# Template register map
Vendor: VendorName Co.Ltd; Series: SeriesName; File version: 1.2
CPU: CM7 r0p1, little endian, MPU, FPU, 4 interrupt priority bits
Registers are 32-bit, read-write, no defined reset value unless marked. A register's access mark holds for its fields unless they carry their own. Offsets are from the block's base; [hi:lo] are bit positions; {n}, {i} and the like mark numbered series.

## SYSCON (part 2 of 2) — System Control
Base 0x40037000
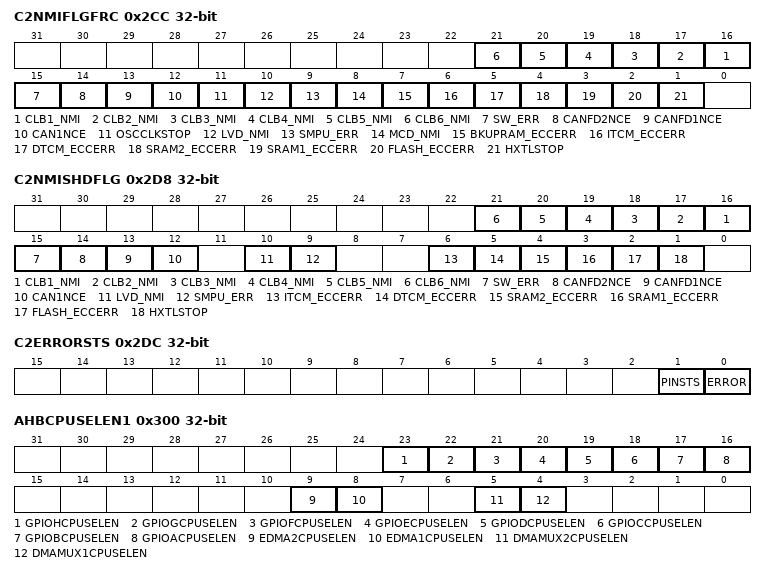
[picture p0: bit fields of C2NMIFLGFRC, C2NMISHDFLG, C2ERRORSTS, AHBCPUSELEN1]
0x2CC C2NMIFLGFRC ro — SYSCON CPU2 NMI flag force read only register
  [n+15] CLB{n}_NMI (n=1..6) — SYSCON CLB{n}_NMI bit: CLB{n} NMI flag force bit of CPU2
  [15] SW_ERR — SYSCON SW_ERR bit: SW ERR flag force bit of CPU2
  [14] CANFD2NCE — SYSCON CANFD2NCE bit: CANFD2 NCE flag force bit of CPU2
  [13] CANFD1NCE — SYSCON CANFD1NCE bit: CANFD1 NCE flag force bit of CPU2
  [12] CAN1NCE — SYSCON CAN1NCE bit: CAN1 NCE flag force bit of CPU2
  [11] OSCCLKSTOP — SYSCON OSCCLKSTOP bit: OSCCLK STOP flag force bit of CPU2
  [10] LVD_NMI — SYSCON LVD_NMI bit: LVD NMI flag force bit of CPU2
  [9] SMPU_ERR — SYSCON SMPU_ERR bit: SMPU ECCERR flag force bit of CPU2
  [8] MCD_NMI — SYSCON MCD_NMI bit: MCD NMI flag force bit of CPU2
  [7] BKUPRAM_ECCERR — SYSCON BKUPRAM_ECCERR bit: BKUPRAM ECCERR flag force bit of CPU2
  [6] ITCM_ECCERR — SYSCON ITCM_ECCERR bit: ITCM ECCERR flag force bit of CPU2
  [5] DTCM_ECCERR — SYSCON DTCM_ECCERR bit: DTCM ECCERR flag force bit of CPU2
  [4] SRAM2_ECCERR — SYSCON SRAM2_ECCERR bit: SRAM2 ECCERR flag force bit of CPU2
  [3] SRAM1_ECCERR — SYSCON SRAM1_ECCERR bit: SRAM1 ECCERR flag force bit of CPU2
  [2] FLASH_ECCERR — SYSCON FLASH_ECCERR bit: FLASH ECCERR flag force bit of CPU2
  [1] HXTLSTOP — SYSCON HXTLSTOP bit: HXTL STOP flag force bit of CPU2
0x2D0 C2NMIWDGCNT ro — SYSCON CPU2 NMIWDG read only register
  [15:0] NMIWDGCNT — SYSCON NMIWDGCNT[15:0] bit: NMIWDG counter of CPU2
0x2D4 C2NMIWDGPRD ro — SYSCON CPU2 NMIWDG period read only register
  [15:0] NMIWDGPRD — SYSCON NMIWDGPRD[15:0] bit: NMIWDG period of CPU2
0x2D8 C2NMISHDFLG ro — SYSCON CPU2 NMI flag shadow read only register
  [n+15] CLB{n}_NMI (n=1..6) — SYSCON CLB{n}_NMI bit: CLB{n} NMI shadow flag bit of CPU2
  [15] SW_ERR — SYSCON SW_ERR bit: SW ERR shadow flag bit of CPU2
  [14] CANFD2NCE — SYSCON CANFD2NCE bit: CANFD2 NCE shadow flag bit of CPU2
  [13] CANFD1NCE — SYSCON CANFD1NCE bit: CANFD1 NCE shadow flag bit of CPU2
  [12] CAN1NCE — SYSCON CAN1NCE bit: CAN1 NCE shadow flag bit of CPU2
  [10] LVD_NMI — SYSCON LVD_NMI bit: LVD NMI shadow flag bit of CPU2
  [9] SMPU_ERR — SYSCON SMPU_ERR bit: SMPU ECCERR shadow flag bit of CPU2
  [6] ITCM_ECCERR — SYSCON ITCM_ECCERR bit: ITCM ECCERR shadow flag bit of CPU2
  [5] DTCM_ECCERR — SYSCON DTCM_ECCERR bit: DTCM ECCERR shadow flag bit of CPU2
  [4] SRAM2_ECCERR — SYSCON SRAM2_ECCERR bit: SRAM2 ECCERR shadow flag bit of CPU2
  [3] SRAM1_ECCERR — SYSCON SRAM1_ECCERR bit: SRAM1 ECCERR shadow flag bit of CPU2
  [2] FLASH_ECCERR — SYSCON FLASH_ECCERR bit: FLASH ECCERR shadow flag bit of CPU2
  [1] HXTLSTOP — SYSCON HXTLSTOP bit: HXTL STOP shadow flag bit of CPU2
0x2DC C2ERRORSTS ro — SYSCON CPU2 error status read only register
  [1] PINSTS — SYSCON PINSTS bit: ERROR pin status bit of CPU2
  [0] ERROR — SYSCON ERROR bit: ERROR status bit of CPU2
0x2E8 C2ERRORCTL ro — SYSCON CPU2 error status control read only register
  [0] ERRORPOL — SYSCON ERRORPOL bit: ERROR polarity select bit of CPU2
0x300 AHBCPUSELEN1 — SYSCON AHB module CPU selection enable register 1
  [23] GPIOHCPUSELEN — SYSCON GPIOHCPUSELEN bit: GPIOH module CPU selection enable
  [22] GPIOGCPUSELEN — SYSCON GPIOGCPUSELEN bit: GPIOG module CPU selection enable
  [21] GPIOFCPUSELEN — SYSCON GPIOFCPUSELEN bit: GPIOF module CPU selection enable
  [20] GPIOECPUSELEN — SYSCON GPIOECPUSELEN bit: GPIOE module CPU selection enable
  [19] GPIODCPUSELEN — SYSCON GPIODCPUSELEN bit: GPIOD module CPU selection enable
  [18] GPIOCCPUSELEN — SYSCON GPIOCCPUSELEN bit: GPIOC module CPU selection enable
  [17] GPIOBCPUSELEN — SYSCON GPIOBCPUSELEN bit: GPIOB module CPU selection enable
  [16] GPIOACPUSELEN — SYSCON GPIOACPUSELEN bit: GPIOA module CPU selection enable
  [9] EDMA2CPUSELEN — SYSCON EDMA2CPUSELEN bit: EDMA2 module CPU selection enable
  [8] EDMA1CPUSELEN — SYSCON EDMA1CPUSELEN bit: EDMA1 module CPU selection enable
  [5] DMAMUX2CPUSELEN — SYSCON DMAMUX2CPUSELEN bit: DMAMUX2 module CPU selection enable
  [4] DMAMUX1CPUSELEN — SYSCON DMAMUX1CPUSELEN bit: DMAMUX1 module CPU selection enable
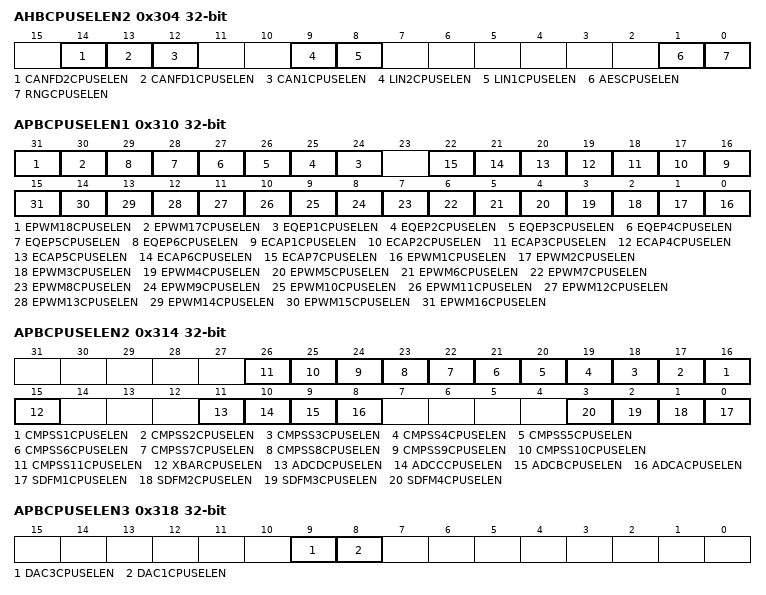
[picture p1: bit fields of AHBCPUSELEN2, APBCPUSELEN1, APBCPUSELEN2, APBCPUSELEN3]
0x304 AHBCPUSELEN2 — SYSCON AHB module CPU selection enable register 2
  [14] CANFD2CPUSELEN — SYSCON CANFD2CPUSELEN bit: CANFD2 module CPU selection enable
  [13] CANFD1CPUSELEN — SYSCON CANFD1CPUSELEN bit: CANFD1 module CPU selection enable
  [12] CAN1CPUSELEN — SYSCON CAN1CPUSELEN bit: CAN1 module CPU selection enable
  [9] LIN2CPUSELEN — SYSCON LIN2CPUSELEN bit: LIN2 module CPU selection enable
  [8] LIN1CPUSELEN — SYSCON LIN1CPUSELEN bit: LIN1 module CPU selection enable
  [1] AESCPUSELEN — SYSCON AESCPUSELEN bit: AES module CPU selection enable
  [0] RNGCPUSELEN — SYSCON RNGCPUSELEN bit: RNG module CPU selection enable
0x310 APBCPUSELEN1 — SYSCON APB module CPU selection enable register 1
  [31] EPWM18CPUSELEN — SYSCON EPWM18CPUSELEN bit: EPWM18 module CPU selection enable
  [30] EPWM17CPUSELEN — SYSCON EPWM17CPUSELEN bit: EPWM17 module CPU selection enable
  [n+23] EQEP{n}CPUSELEN (n=1..6) — SYSCON EQEP{n}CPUSELEN bit: EQEP{n} module CPU selection enable
  [n+15] ECAP{n}CPUSELEN (n=1..7) — SYSCON ECAP{n}CPUSELEN bit: ECAP{n} module CPU selection enable
  [n-1] EPWM{n}CPUSELEN (n=1..16) — SYSCON EPWM{n}CPUSELEN bit: EPWM{n} module CPU selection enable
0x314 APBCPUSELEN2 — SYSCON APB module CPU selection enable register 2
  [n+15] CMPSS{n}CPUSELEN (n=1..11) — SYSCON CMPSS{n}CPUSELEN bit: CMPSS{n} module CPU selection enable
  [15] XBARCPUSELEN — SYSCON XBARCPUSELEN bit: XBAR module CPU selection enable
  [11] ADCDCPUSELEN — SYSCON ADCDCPUSELEN bit: ADCD module CPU selection enable
  [10] ADCCCPUSELEN — SYSCON ADCCCPUSELEN bit: ADCC module CPU selection enable
  [9] ADCBCPUSELEN — SYSCON ADCBCPUSELEN bit: ADCB module CPU selection enable
  [8] ADCACPUSELEN — SYSCON ADCACPUSELEN bit: ADCA module CPU selection enable
  [n-1] SDFM{n}CPUSELEN (n=1..4) — SYSCON SDFM{n}CPUSELEN bit: SDFM{n} module CPU selection enable
0x318 APBCPUSELEN3 — SYSCON APB module CPU selection enable register 3
  [9] DAC3CPUSELEN — SYSCON DAC3CPUSELEN bit: DAC3 module CPU selection enable
  [8] DAC1CPUSELEN — SYSCON DAC1CPUSELEN bit: DAC1 module CPU selection enable
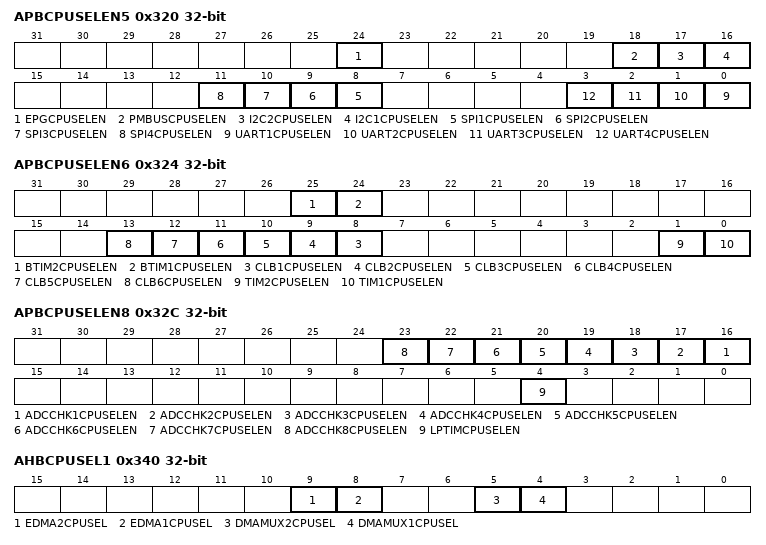
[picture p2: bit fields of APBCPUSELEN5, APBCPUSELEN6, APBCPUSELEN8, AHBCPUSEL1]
0x320 APBCPUSELEN5 — SYSCON APB module CPU selection enable register 5
  [24] EPGCPUSELEN — SYSCON EPGCPUSELEN bit: EPG module CPU selection enable
  [18] PMBUSCPUSELEN — SYSCON PMBUSCPUSELEN bit: PMBUS module CPU selection enable
  [17] I2C2CPUSELEN — SYSCON I2C2CPUSELEN bit: I2C2 module CPU selection enable
  [16] I2C1CPUSELEN — SYSCON I2C1CPUSELEN bit: I2C1 module CPU selection enable
  [n+7] SPI{n}CPUSELEN (n=1..4) — SYSCON SPI{n}CPUSELEN bit: SPI{n} module CPU selection enable
  [n-1] UART{n}CPUSELEN (n=1..4) — SYSCON UART{n}CPUSELEN bit: UART{n} module CPU selection enable
0x324 APBCPUSELEN6 — SYSCON APB module CPU selection enable register 6
  [25] BTIM2CPUSELEN — SYSCON BTIM2CPUSELEN bit: BTIM2 module CPU selection enable
  [24] BTIM1CPUSELEN — SYSCON BTIM1CPUSELEN bit: BTIM1 module CPU selection enable
  [n+7] CLB{n}CPUSELEN (n=1..6) — SYSCON CLB{n}CPUSELEN bit: CLB{n} module CPU selection enable
  [1] TIM2CPUSELEN — SYSCON TIM2CPUSELEN bit: TIM2 module CPU selection enable
  [0] TIM1CPUSELEN — SYSCON TIM1CPUSELEN bit: TIM1 module CPU selection enable
0x32C APBCPUSELEN8 — SYSCON APB module CPU selection enable register 8
  [n+15] ADCCHK{n}CPUSELEN (n=1..8) — SYSCON ADCCHK{n}CPUSELEN bit: ADC CHECKER{n} module CPU selection enable
  [4] LPTIMCPUSELEN — SYSCON LPTIMCPUSELEN bit: LPTIM module CPU selection enable
0x340 AHBCPUSEL1 — SYSCON AHB module CPU select register 1
  [9] EDMA2CPUSEL — SYSCON EDMA2CPUSEL bit: EDMA2 module CPU select
  [8] EDMA1CPUSEL — SYSCON EDMA1CPUSEL bit: EDMA1 module CPU select
  [5] DMAMUX2CPUSEL — SYSCON DMAMUX2CPUSEL bit: DMAMUX2 module CPU select
  [4] DMAMUX1CPUSEL — SYSCON DMAMUX1CPUSEL bit: DMAMUX1 module CPU select
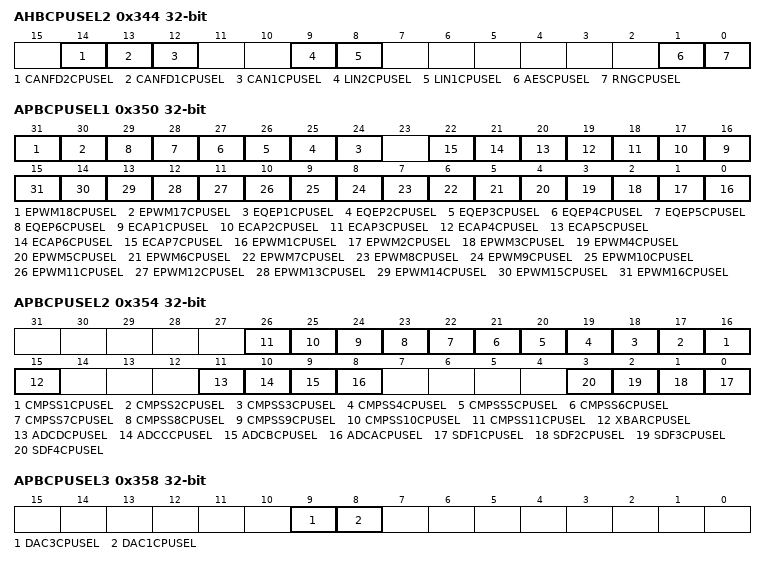
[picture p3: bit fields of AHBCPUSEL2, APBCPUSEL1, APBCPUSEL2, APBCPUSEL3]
0x344 AHBCPUSEL2 — SYSCON AHB module CPU select register 2
  [14] CANFD2CPUSEL — SYSCON CANFD2CPUSEL bit: CANFD2 module CPU select
  [13] CANFD1CPUSEL — SYSCON CANFD1CPUSEL bit: CANFD1 module CPU select
  [12] CAN1CPUSEL — SYSCON CAN1CPUSEL bit: CAN1 module CPU select
  [9] LIN2CPUSEL — SYSCON LIN2CPUSEL bit: LIN2 module CPU select
  [8] LIN1CPUSEL — SYSCON LIN1CPUSEL bit: LIN1 module CPU select
  [1] AESCPUSEL — SYSCON AESCPUSEL bit: AES module CPU select
  [0] RNGCPUSEL — SYSCON RNGCPUSEL bit: RNG module CPU select
0x350 APBCPUSEL1 — SYSCON APB module CPU select register 1
  [31] EPWM18CPUSEL — SYSCON EPWM18CPUSEL bit: EPWM18 module CPU select
  [30] EPWM17CPUSEL — SYSCON EPWM17CPUSEL bit: EPWM17 module CPU select
  [n+23] EQEP{n}CPUSEL (n=1..6) — SYSCON EQEP{n}CPUSEL bit: EQEP{n} module CPU select
  [n+15] ECAP{n}CPUSEL (n=1..7) — SYSCON ECAP{n}CPUSEL bit: ECAP{n} module CPU select
  [n-1] EPWM{n}CPUSEL (n=1..16) — SYSCON EPWM{n}CPUSEL bit: EPWM{n} module CPU select
0x354 APBCPUSEL2 — SYSCON APB module CPU select register 2
  [n+15] CMPSS{n}CPUSEL (n=1..11) — SYSCON CMPSS{n}CPUSEL bit: CMPSS{n} module CPU select
  [15] XBARCPUSEL — SYSCON XBARCPUSEL bit: XBAR module CPU select
  [11] ADCDCPUSEL — SYSCON ADCDCPUSEL bit: ADCD module CPU select
  [10] ADCCCPUSEL — SYSCON ADCCCPUSEL bit: ADCC module CPU select
  [9] ADCBCPUSEL — SYSCON ADCBCPUSEL bit: ADCB module CPU select
  [8] ADCACPUSEL — SYSCON ADCACPUSEL bit: ADCA module CPU select
  [n-1] SDF{n}CPUSEL (n=1..4) — SYSCON SDF{n}CPUSEL bit: SDF{n} module CPU select
0x358 APBCPUSEL3 — SYSCON APB module CPU select register 3
  [9] DAC3CPUSEL — SYSCON DAC3CPUSEL bit: DAC3 module CPU select
  [8] DAC1CPUSEL — SYSCON DAC1CPUSEL bit: DAC1 module CPU select
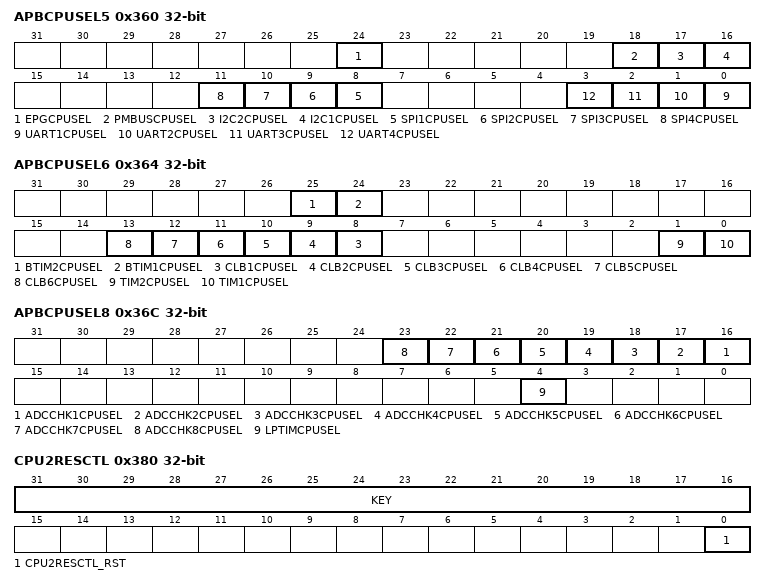
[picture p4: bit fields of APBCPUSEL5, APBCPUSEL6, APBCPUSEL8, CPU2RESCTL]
0x360 APBCPUSEL5 — SYSCON APB module CPU select register 5
  [24] EPGCPUSEL — SYSCON EPGCPUSEL bit: EPG module CPU select
  [18] PMBUSCPUSEL — SYSCON PMBUSCPUSEL bit: PMBUS module CPU select
  [17] I2C2CPUSEL — SYSCON I2C2CPUSEL bit: I2C2 module CPU select
  [16] I2C1CPUSEL — SYSCON I2C1CPUSEL bit: I2C1 module CPU select
  [n+7] SPI{n}CPUSEL (n=1..4) — SYSCON SPI{n}CPUSEL bit: SPI{n} module CPU select
  [n-1] UART{n}CPUSEL (n=1..4) — SYSCON UART{n}CPUSEL bit: UART{n} module CPU select
0x364 APBCPUSEL6 — SYSCON APB module CPU select register 6
  [25] BTIM2CPUSEL — SYSCON BTIM2CPUSEL bit: BTIM2 module CPU select
  [24] BTIM1CPUSEL — SYSCON BTIM1CPUSEL bit: BTIM1 module CPU select
  [n+7] CLB{n}CPUSEL (n=1..6) — SYSCON CLB{n}CPUSEL bit: CLB{n} module CPU select
  [1] TIM2CPUSEL — SYSCON TIM2CPUSEL bit: TIM2 module CPU select
  [0] TIM1CPUSEL — SYSCON TIM1CPUSEL bit: TIM1 module CPU select
0x36C APBCPUSEL8 — SYSCON APB module CPU select register 8
  [n+15] ADCCHK{n}CPUSEL (n=1..8) — SYSCON ADCCHK{n}CPUSEL bit: ADC CHECKER{n} module CPU select
  [4] LPTIMCPUSEL — SYSCON LPTIMCPUSEL bit: LPTIM module CPU select
0x380 CPU2RESCTL — SYSCON CPU2 reset control register
  [31:16] KEY wo — SYSCON KEY[15:0] bit: only when 0xA5A5 is written at high position can this register be written
  [0] CPU2RESCTL_RST — SYSCON CPU2RESCTL_RST bit: CPU2 reset control
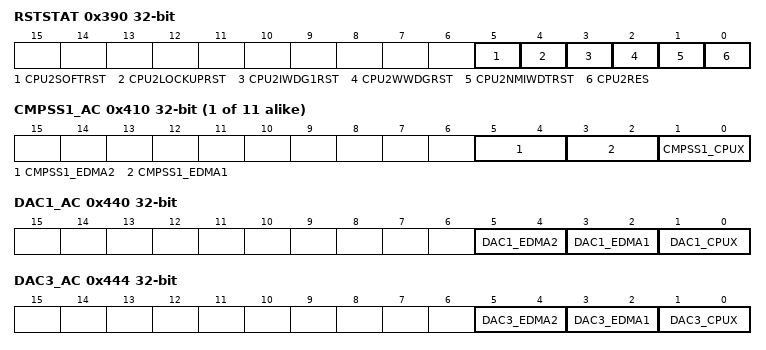
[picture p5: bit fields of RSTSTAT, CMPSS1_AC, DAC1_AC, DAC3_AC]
0x390 RSTSTAT — SYSCON CPU2 reset status register
  [5] CPU2SOFTRST — SYSCON CPU2SOFTRST bit: CPU2 was reseted by CPU2.SOFT
  [4] CPU2LOCKUPRST — SYSCON CPU2LOCKUPRST bit: CPU2 was reseted by CPU2.LOCKUP
  [3] CPU2IWDG1RST — SYSCON CPU2IWDG1RST bit: CPU2 was reseted by CPU2.IWDG1
  [2] CPU2WWDGRST — SYSCON CPU2WWDGRST bit: CPU2 was reseted by CPU2.WWDG
  [1] CPU2NMIWDTRST — SYSCON CPU2NMIWDTRST bit: CPU2 was reseted by CPU2.NMIWDT
  [0] CPU2RES ro — SYSCON CPU2RES bit: CPU2 reset status
0x400 ADCA_AC — SYSCON ADCA access control register
  [1:0] ADCA_CPUX — SYSCON ADCA_CPUX[1:0] bit: ADCA CPUx access privilege
0x404 ADCB_AC — SYSCON ADCB access control register
  [1:0] ADCB_CPUX — SYSCON ADCB_CPUX[1:0] bit: ADCB CPUx access privilege
0x408 ADCC_AC — SYSCON ADCC access control register
  [1:0] ADCC_CPUX — SYSCON ADCC_CPUX[1:0] bit: ADCC CPUx access privilege
0x40C ADCD_AC — SYSCON ADCD access control register
  [1:0] ADCD_CPUX — SYSCON ADCD_CPUX[1:0] bit: ADCD CPUx access privilege
{0x40C+4i} CMPSS{i}_AC (i=1..11) — SYSCON CMPSS{i} access control register
  [5:4] CMPSS{i}_EDMA2 — SYSCON CMPSS{i}_EDMA2[1:0] bit: CMPSS{i} EDMA2 access privilege
  [3:2] CMPSS{i}_EDMA1 — SYSCON CMPSS{i}_EDMA1[1:0] bit: CMPSS{i} EDMA1 access privilege
  [1:0] CMPSS{i}_CPUX — SYSCON CMPSS{i}_CPUX[1:0] bit: CMPSS{i} CPUx access privilege
0x440 DAC1_AC — SYSCON DAC1 access control register
  [5:4] DAC1_EDMA2 — SYSCON DAC1_EDMA2[1:0] bit: DAC1 EDMA2 access privilege
  [3:2] DAC1_EDMA1 — SYSCON DAC1_EDMA1[1:0] bit: DAC1 EDMA1 access privilege
  [1:0] DAC1_CPUX — SYSCON DAC1_CPUX[1:0] bit: DAC1 CPUx access privilege
0x444 DAC3_AC — SYSCON DAC3 access control register
  [5:4] DAC3_EDMA2 — SYSCON DAC3_EDMA2[1:0] bit: DAC3 EDMA2 access privilege
  [3:2] DAC3_EDMA1 — SYSCON DAC3_EDMA1[1:0] bit: DAC3 EDMA1 access privilege
  [1:0] DAC3_CPUX — SYSCON DAC3_CPUX[1:0] bit: DAC3 CPUx access privilege
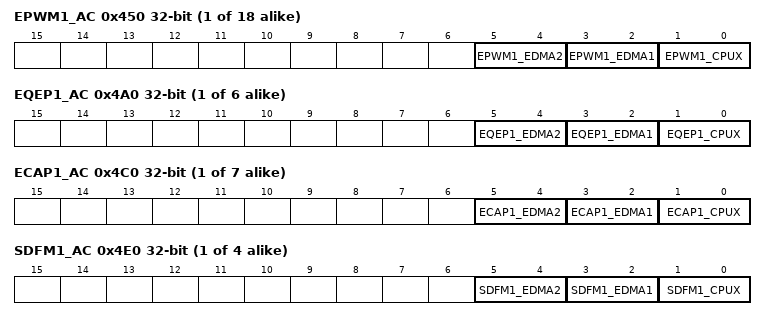
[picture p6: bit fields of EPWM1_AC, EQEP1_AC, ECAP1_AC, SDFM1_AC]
{0x44C+4i} EPWM{i}_AC (i=1..18) — SYSCON EPWM{i} access control register
  [5:4] EPWM{i}_EDMA2 — SYSCON EPWM{i}_EDMA2[1:0] bit: EPWM{i} EDMA2 access privilege
  [3:2] EPWM{i}_EDMA1 — SYSCON EPWM{i}_EDMA1[1:0] bit: EPWM{i} EDMA1 access privilege
  [1:0] EPWM{i}_CPUX — SYSCON EPWM{i}_CPUX[1:0] bit: EPWM{i} CPUx access privilege
{0x49C+4i} EQEP{i}_AC (i=1..6) — SYSCON EQEP{i} access control register
  [5:4] EQEP{i}_EDMA2 — SYSCON EQEP{i}_EDMA2[1:0] bit: EQEP{i} EDMA2 access privilege
  [3:2] EQEP{i}_EDMA1 — SYSCON EQEP{i}_EDMA1[1:0] bit: EQEP{i} EDMA1 access privilege
  [1:0] EQEP{i}_CPUX — SYSCON EQEP{i}_CPUX[1:0] bit: EQEP{i} CPUx access privilege
{0x4BC+4i} ECAP{i}_AC (i=1..7) — SYSCON ECAP{i} access control register
  [5:4] ECAP{i}_EDMA2 — SYSCON ECAP{i}_EDMA2[1:0] bit: ECAP{i} EDMA2 access privilege
  [3:2] ECAP{i}_EDMA1 — SYSCON ECAP{i}_EDMA1[1:0] bit: ECAP{i} EDMA1 access privilege
  [1:0] ECAP{i}_CPUX — SYSCON ECAP{i}_CPUX[1:0] bit: ECAP{i} CPUx access privilege
{0x4DC+4i} SDFM{i}_AC (i=1..4) — SYSCON SDFM{i} access control register
  [5:4] SDFM{i}_EDMA2 — SYSCON SDFM{i}_EDMA2[1:0] bit: SDFM{i} EDMA2 access privilege
  [3:2] SDFM{i}_EDMA1 — SYSCON SDFM{i}_EDMA1[1:0] bit: SDFM{i} EDMA1 access privilege
  [1:0] SDFM{i}_CPUX — SYSCON SDFM{i}_CPUX[1:0] bit: SDFM{i} CPUx access privilege
{0x4EC+4i} CLB{i}_AC (i=1..6) — SYSCON CLB{i} access control register
  [1:0] CLB{i}_CPUX — SYSCON CLB{i}_CPUX[1:0] bit: CLB{i} CPUx access privilege
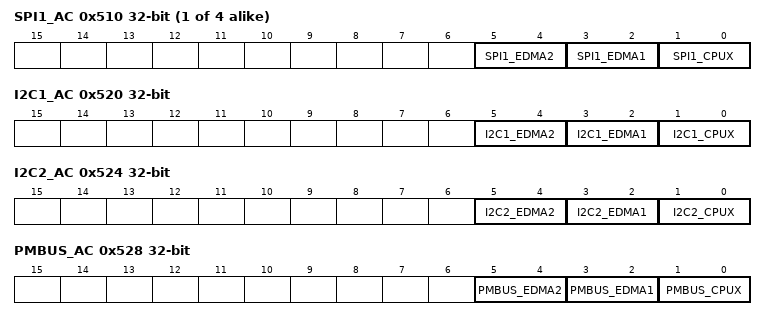
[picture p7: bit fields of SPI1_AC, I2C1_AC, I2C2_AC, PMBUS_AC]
{0x50C+4i} SPI{i}_AC (i=1..4) — SYSCON SPI{i} access control register
  [5:4] SPI{i}_EDMA2 — SYSCON SPI{i}_EDMA2[1:0] bit: SPI{i} EDMA2 access privilege
  [3:2] SPI{i}_EDMA1 — SYSCON SPI{i}_EDMA1[1:0] bit: SPI{i} EDMA1 access privilege
  [1:0] SPI{i}_CPUX — SYSCON SPI{i}_CPUX[1:0] bit: SPI{i} CPUx access privilege
0x520 I2C1_AC — SYSCON I2C1 access control register
  [5:4] I2C1_EDMA2 — SYSCON I2C1_EDMA2[1:0] bit: I2C1 EDMA2 access privilege
  [3:2] I2C1_EDMA1 — SYSCON I2C1_EDMA1[1:0] bit: I2C1 EDMA1 access privilege
  [1:0] I2C1_CPUX — SYSCON I2C1_CPUX[1:0] bit: I2C1 CPUx access privilege
0x524 I2C2_AC — SYSCON I2C2 access control register
  [5:4] I2C2_EDMA2 — SYSCON I2C2_EDMA2[1:0] bit: I2C2 EDMA2 access privilege
  [3:2] I2C2_EDMA1 — SYSCON I2C2_EDMA1[1:0] bit: I2C2 EDMA1 access privilege
  [1:0] I2C2_CPUX — SYSCON I2C2_CPUX[1:0] bit: I2C2 CPUx access privilege
0x528 PMBUS_AC — SYSCON PMBUS access control register
  [5:4] PMBUS_EDMA2 — SYSCON PMBUS_EDMA2[1:0] bit: PMBUS EDMA2 access privilege
  [3:2] PMBUS_EDMA1 — SYSCON PMBUS_EDMA1[1:0] bit: PMBUS EDMA1 access privilege
  [1:0] PMBUS_CPUX — SYSCON PMBUS_CPUX[1:0] bit: PMBUS CPUx access privilege
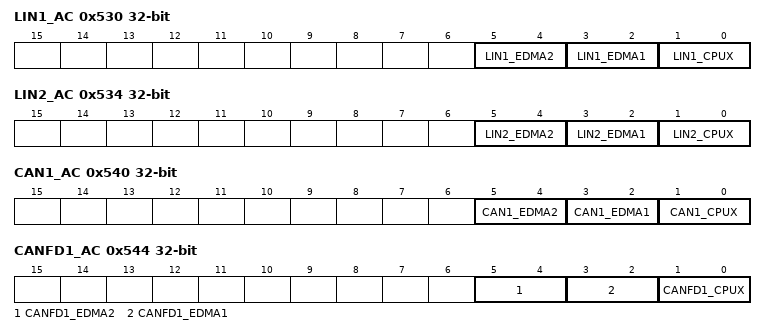
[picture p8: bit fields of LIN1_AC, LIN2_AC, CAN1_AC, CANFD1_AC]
0x530 LIN1_AC — SYSCON LIN1 access control register
  [5:4] LIN1_EDMA2 — SYSCON LIN1_EDMA2[1:0] bit: LIN1 EDMA2 access privilege
  [3:2] LIN1_EDMA1 — SYSCON LIN1_EDMA1[1:0] bit: LIN1 EDMA1 access privilege
  [1:0] LIN1_CPUX — SYSCON LIN1_CPUX[1:0] bit: LIN1 CPUx access privilege
0x534 LIN2_AC — SYSCON LIN2 access control register
  [5:4] LIN2_EDMA2 — SYSCON LIN2_EDMA2[1:0] bit: LIN2 EDMA2 access privilege
  [3:2] LIN2_EDMA1 — SYSCON LIN2_EDMA1[1:0] bit: LIN2 EDMA1 access privilege
  [1:0] LIN2_CPUX — SYSCON LIN2_CPUX[1:0] bit: LIN2 CPUx access privilege
0x540 CAN1_AC — SYSCON CAN1 access control register
  [5:4] CAN1_EDMA2 — SYSCON CAN1_EDMA2[1:0] bit: CAN1 EDMA2 access privilege
  [3:2] CAN1_EDMA1 — SYSCON CAN1_EDMA1[1:0] bit: CAN1 EDMA1 access privilege
  [1:0] CAN1_CPUX — SYSCON CAN1_CPUX[1:0] bit: CAN1 CPUx access privilege
0x544 CANFD1_AC — SYSCON CANFD1 access control register
  [5:4] CANFD1_EDMA2 — SYSCON CANFD1_EDMA2[1:0] bit: CANFD1 EDMA2 access privilege
  [3:2] CANFD1_EDMA1 — SYSCON CANFD1_EDMA1[1:0] bit: CANFD1 EDMA1 access privilege
  [1:0] CANFD1_CPUX — SYSCON CANFD1_CPUX[1:0] bit: CANFD1 CPUx access privilege
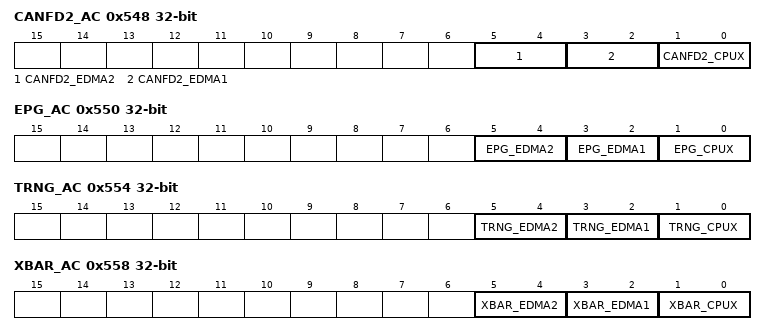
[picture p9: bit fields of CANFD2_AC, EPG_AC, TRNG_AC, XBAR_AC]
0x548 CANFD2_AC — SYSCON CANFD2 access control register
  [5:4] CANFD2_EDMA2 — SYSCON CANFD2_EDMA2[1:0] bit: CANFD2 EDMA2 access privilege
  [3:2] CANFD2_EDMA1 — SYSCON CANFD2_EDMA1[1:0] bit: CANFD2 EDMA1 access privilege
  [1:0] CANFD2_CPUX — SYSCON CANFD2_CPUX[1:0] bit: CANFD2 CPUx access privilege
0x550 EPG_AC — SYSCON EPG access control register
  [5:4] EPG_EDMA2 — SYSCON EPG_EDMA2[1:0] bit: EPG EDMA2 access privilege
  [3:2] EPG_EDMA1 — SYSCON EPG_EDMA1[1:0] bit: EPG EDMA1 access privilege
  [1:0] EPG_CPUX — SYSCON EPG_CPUX[1:0] bit: EPG CPUx access privilege
0x554 TRNG_AC — SYSCON TRNG access control register
  [5:4] TRNG_EDMA2 — SYSCON TRNG_EDMA2[1:0] bit: TRNG EDMA2 access privilege
  [3:2] TRNG_EDMA1 — SYSCON TRNG_EDMA1[1:0] bit: TRNG EDMA1 access privilege
  [1:0] TRNG_CPUX — SYSCON TRNG_CPUX[1:0] bit: TRNG CPUx access privilege
0x558 XBAR_AC — SYSCON XBAR access control register
  [5:4] XBAR_EDMA2 — SYSCON XBAR_EDMA2[1:0] bit: XBAR EDMA2 access privilege
  [3:2] XBAR_EDMA1 — SYSCON XBAR_EDMA1[1:0] bit: XBAR EDMA1 access privilege
  [1:0] XBAR_CPUX — SYSCON XBAR_CPUX[1:0] bit: XBAR CPUx access privilege
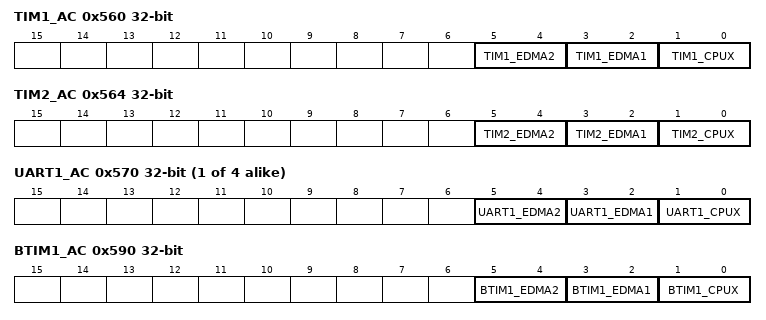
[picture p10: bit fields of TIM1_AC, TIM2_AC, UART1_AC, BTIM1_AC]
0x560 TIM1_AC — SYSCON TIM1 access control register
  [5:4] TIM1_EDMA2 — SYSCON TIM1_EDMA2[1:0] bit: TIM1 EDMA2 access privilege
  [3:2] TIM1_EDMA1 — SYSCON TIM1_EDMA1[1:0] bit: TIM1 EDMA1 access privilege
  [1:0] TIM1_CPUX — SYSCON TIM1_CPUX[1:0] bit: TIM1 CPUx access privilege
0x564 TIM2_AC — SYSCON TIM2 access control register
  [5:4] TIM2_EDMA2 — SYSCON TIM2_EDMA2[1:0] bit: TIM2 EDMA2 access privilege
  [3:2] TIM2_EDMA1 — SYSCON TIM2_EDMA1[1:0] bit: TIM2 EDMA1 access privilege
  [1:0] TIM2_CPUX — SYSCON TIM2_CPUX[1:0] bit: TIM2 CPUx access privilege
0x56C LPTIM_AC — SYSCON LPTIM access control register
  [1:0] LPTIM_CPUX — SYSCON LPTIM_CPUX[1:0] bit: LPTIM CPUx access privilege
{0x56C+4i} UART{i}_AC (i=1..4) — SYSCON UART{i} access control register
  [5:4] UART{i}_EDMA2 — SYSCON UART{i}_EDMA2[1:0] bit: UART{i} EDMA2 access privilege
  [3:2] UART{i}_EDMA1 — SYSCON UART{i}_EDMA1[1:0] bit: UART{i} EDMA1 access privilege
  [1:0] UART{i}_CPUX — SYSCON UART{i}_CPUX[1:0] bit: UART{i} CPUx access privilege
0x580 EDMA1_AC — SYSCON EDMA1 access control register
  [1:0] EDMA1_CPUX — SYSCON EDMA1_CPUX[1:0] bit: EDMA1 CPUx access privilege
0x584 EDMA2_AC — SYSCON EDMA2 access control register
  [1:0] EDMA2_CPUX — SYSCON EDMA2_CPUX[1:0] bit: EDMA2 CPUx access privilege
0x588 DMAMUX1_AC — SYSCON DMAMUX1 access control register
  [1:0] DMAMUX1_CPUX — SYSCON DMAMUX1_CPUX[1:0] bit: DMAMUX1 CPUx access privilege
0x58C DMAMUX2_AC — SYSCON DMAMUX2 access control register
  [1:0] DMAMUX2_CPUX — SYSCON DMAMUX2_CPUX[1:0] bit: DMAMUX2 CPUx access privilege
0x590 BTIM1_AC — SYSCON BTIM1 access control register
  [5:4] BTIM1_EDMA2 — SYSCON BTIM1_EDMA2[1:0] bit: BTIM1 EDMA2 access privilege
  [3:2] BTIM1_EDMA1 — SYSCON BTIM1_EDMA1[1:0] bit: BTIM1 EDMA1 access privilege
  [1:0] BTIM1_CPUX — SYSCON BTIM1_CPUX[1:0] bit: BTIM1 CPUx access privilege
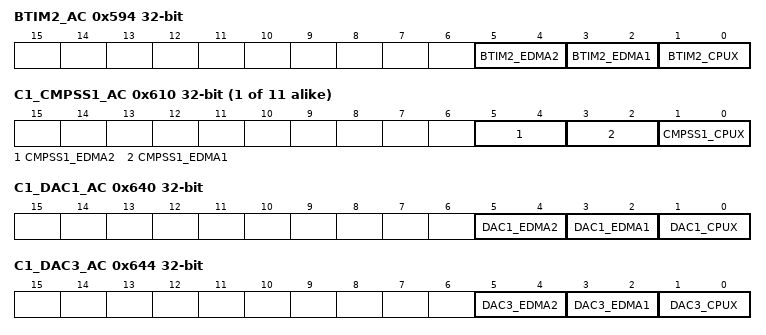
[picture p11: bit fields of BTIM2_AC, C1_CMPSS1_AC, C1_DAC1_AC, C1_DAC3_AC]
0x594 BTIM2_AC — SYSCON BTIM2 access control register
  [5:4] BTIM2_EDMA2 — SYSCON BTIM2_EDMA2[1:0] bit: BTIM2 EDMA2 access privilege
  [3:2] BTIM2_EDMA1 — SYSCON BTIM2_EDMA1[1:0] bit: BTIM2 EDMA1 access privilege
  [1:0] BTIM2_CPUX — SYSCON BTIM2_CPUX[1:0] bit: BTIM2 CPUx access privilege
0x5FC PERIPH_AC_LOCK — SYSCON access control lock register
  [0] LOCK_AC_WR — SYSCON LOCK_AC_WR bit: CPUx peripheral access control register access privilege
0x600 C1_ADCA_AC ro — SYSCON CPU1 ADCA access control read only register
  [1:0] ADCA_CPUX — SYSCON ADCA_CPUX[1:0] bit: ADCA CPUx access privilege of CPU1
0x604 C1_ADCB_AC ro — SYSCON CPU1 ADCB access control read only register
  [1:0] ADCB_CPUX — SYSCON ADCB_CPUX[1:0] bit: ADCB CPUx access privilege of CPU1
0x608 C1_ADCC_AC ro — SYSCON CPU1 ADCC access control read only register
  [1:0] ADCC_CPUX — SYSCON ADCC_CPUX[1:0] bit: ADCC CPUx access privilege of CPU1
0x60C C1_ADCD_AC ro — SYSCON CPU1 ADCD access control read only register
  [1:0] ADCD_CPUX — SYSCON ADCD_CPUX[1:0] bit: ADCD CPUx access privilege of CPU1
{0x60C+4i} C1_CMPSS{i}_AC ro (i=1..11) — SYSCON CPU1 CMPSS{i} access control read only register
  [5:4] CMPSS{i}_EDMA2 — SYSCON CMPSS{i}_EDMA2[1:0] bit: CMPSS{i} EDMA2 access privilege of CPU1
  [3:2] CMPSS{i}_EDMA1 — SYSCON CMPSS{i}_EDMA1[1:0] bit: CMPSS{i} EDMA1 access privilege of CPU1
  [1:0] CMPSS{i}_CPUX — SYSCON CMPSS{i}_CPUX[1:0] bit: CMPSS{i} CPUx access privilege of CPU1
0x640 C1_DAC1_AC ro — SYSCON CPU1 DAC1 access control read only register
  [5:4] DAC1_EDMA2 — SYSCON DAC1_EDMA2[1:0] bit: DAC1 EDMA2 access privilege of CPU1
  [3:2] DAC1_EDMA1 — SYSCON DAC1_EDMA1[1:0] bit: DAC1 EDMA1 access privilege of CPU1
  [1:0] DAC1_CPUX — SYSCON DAC1_CPUX[1:0] bit: DAC1 CPUx access privilege of CPU1
0x644 C1_DAC3_AC ro — SYSCON CPU1 DAC3 access control read only register
  [5:4] DAC3_EDMA2 — SYSCON DAC3_EDMA2[1:0] bit: DAC3 EDMA2 access privilege of CPU1
  [3:2] DAC3_EDMA1 — SYSCON DAC3_EDMA1[1:0] bit: DAC3 EDMA1 access privilege of CPU1
  [1:0] DAC3_CPUX — SYSCON DAC3_CPUX[1:0] bit: DAC3 CPUx access privilege of CPU1
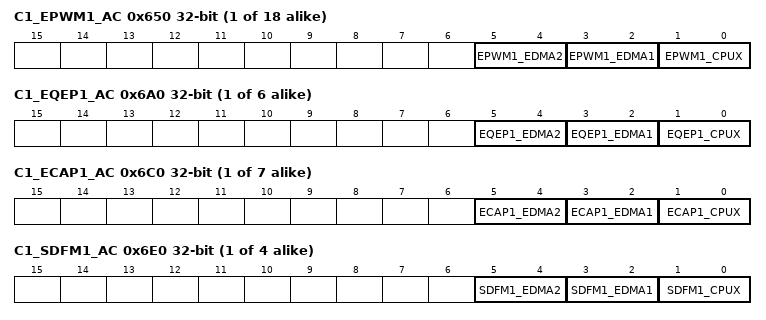
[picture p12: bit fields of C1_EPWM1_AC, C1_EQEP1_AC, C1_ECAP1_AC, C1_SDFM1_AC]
{0x64C+4i} C1_EPWM{i}_AC ro (i=1..18) — SYSCON CPU1 EPWM{i} access control read only register
  [5:4] EPWM{i}_EDMA2 — SYSCON EPWM{i}_EDMA2[1:0] bit: EPWM{i} EDMA2 access privilege of CPU1
  [3:2] EPWM{i}_EDMA1 — SYSCON EPWM{i}_EDMA1[1:0] bit: EPWM{i} EDMA1 access privilege of CPU1
  [1:0] EPWM{i}_CPUX — SYSCON EPWM{i}_CPUX[1:0] bit: EPWM{i} CPUx access privilege of CPU1
{0x69C+4i} C1_EQEP{i}_AC ro (i=1..6) — SYSCON CPU1 EQEP{i} access control read only register
  [5:4] EQEP{i}_EDMA2 — SYSCON EQEP{i}_EDMA2[1:0] bit: EQEP{i} EDMA2 access privilege of CPU1
  [3:2] EQEP{i}_EDMA1 — SYSCON EQEP{i}_EDMA1[1:0] bit: EQEP{i} EDMA1 access privilege of CPU1
  [1:0] EQEP{i}_CPUX — SYSCON EQEP{i}_CPUX[1:0] bit: EQEP{i} CPUx access privilege of CPU1
{0x6BC+4i} C1_ECAP{i}_AC ro (i=1..7) — SYSCON CPU1 ECAP{i} access control read only register
  [5:4] ECAP{i}_EDMA2 — SYSCON ECAP{i}_EDMA2[1:0] bit: ECAP{i} EDMA2 access privilege of CPU1
  [3:2] ECAP{i}_EDMA1 — SYSCON ECAP{i}_EDMA1[1:0] bit: ECAP{i} EDMA1 access privilege of CPU1
  [1:0] ECAP{i}_CPUX — SYSCON ECAP{i}_CPUX[1:0] bit: ECAP{i} CPUx access privilege of CPU1
{0x6DC+4i} C1_SDFM{i}_AC ro (i=1..4) — SYSCON CPU1 SDFM{i} access control read only register
  [5:4] SDFM{i}_EDMA2 — SYSCON SDFM{i}_EDMA2[1:0] bit: SDFM{i} EDMA2 access privilege of CPU1
  [3:2] SDFM{i}_EDMA1 — SYSCON SDFM{i}_EDMA1[1:0] bit: SDFM{i} EDMA1 access privilege of CPU1
  [1:0] SDFM{i}_CPUX — SYSCON SDFM{i}_CPUX[1:0] bit: SDFM{i} CPUx access privilege of CPU1
{0x6EC+4i} C1_CLB{i}_AC ro (i=1..6) — SYSCON CPU1 CLB{i} access control read only register
  [1:0] CLB{i}_CPUX — SYSCON CLB{i}_CPUX[1:0] bit: CLB{i} CPUx access privilege of CPU1
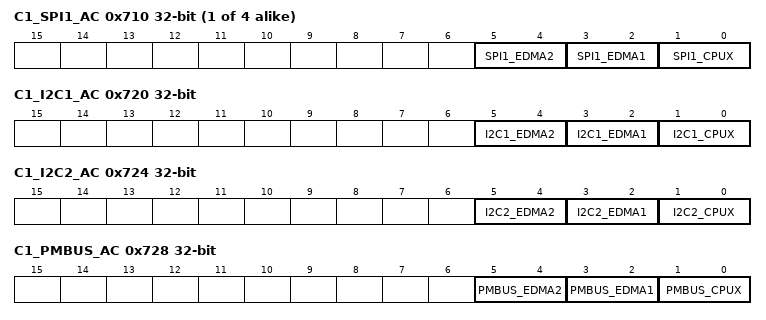
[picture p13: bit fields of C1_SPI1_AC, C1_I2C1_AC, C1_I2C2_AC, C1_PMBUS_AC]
{0x70C+4i} C1_SPI{i}_AC ro (i=1..4) — SYSCON CPU1 SPI{i} access control read only register
  [5:4] SPI{i}_EDMA2 — SYSCON SPI{i}_EDMA2[1:0] bit: SPI{i} EDMA2 access privilege of CPU1
  [3:2] SPI{i}_EDMA1 — SYSCON SPI{i}_EDMA1[1:0] bit: SPI{i} EDMA1 access privilege of CPU1
  [1:0] SPI{i}_CPUX — SYSCON SPI{i}_CPUX[1:0] bit: SPI{i} CPUx access privilege of CPU1
0x720 C1_I2C1_AC ro — SYSCON CPU1 I2C1 access control read only register
  [5:4] I2C1_EDMA2 — SYSCON I2C1_EDMA2[1:0] bit: I2C1 EDMA2 access privilege of CPU1
  [3:2] I2C1_EDMA1 — SYSCON I2C1_EDMA1[1:0] bit: I2C1 EDMA1 access privilege of CPU1
  [1:0] I2C1_CPUX — SYSCON I2C1_CPUX[1:0] bit: I2C1 CPUx access privilege of CPU1
0x724 C1_I2C2_AC ro — SYSCON CPU1 I2C2 access control read only register
  [5:4] I2C2_EDMA2 — SYSCON I2C2_EDMA2[1:0] bit: I2C2 EDMA2 access privilege of CPU1
  [3:2] I2C2_EDMA1 — SYSCON I2C2_EDMA1[1:0] bit: I2C2 EDMA1 access privilege of CPU1
  [1:0] I2C2_CPUX — SYSCON I2C2_CPUX[1:0] bit: I2C2 CPUx access privilege of CPU1
0x728 C1_PMBUS_AC ro — SYSCON CPU1 PMBUS access control read only register
  [5:4] PMBUS_EDMA2 — SYSCON PMBUS_EDMA2[1:0] bit: PMBUS EDMA2 access privilege of CPU1
  [3:2] PMBUS_EDMA1 — SYSCON PMBUS_EDMA1[1:0] bit: PMBUS EDMA1 access privilege of CPU1
  [1:0] PMBUS_CPUX — SYSCON PMBUS_CPUX[1:0] bit: PMBUS CPUx access privilege of CPU1
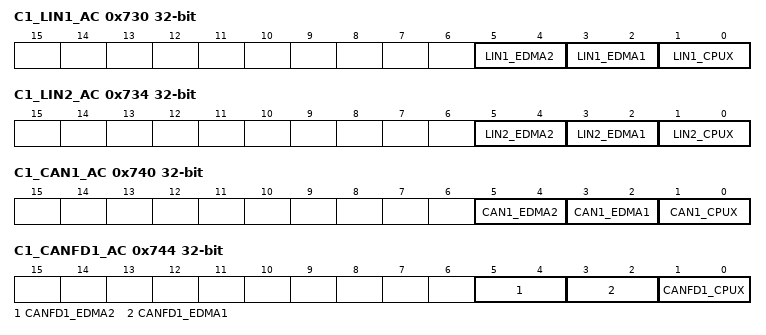
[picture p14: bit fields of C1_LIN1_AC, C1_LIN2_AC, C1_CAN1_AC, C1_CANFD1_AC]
0x730 C1_LIN1_AC ro — SYSCON CPU1 LIN1 access control read only register
  [5:4] LIN1_EDMA2 — SYSCON LIN1_EDMA2[1:0] bit: LIN1 EDMA2 access privilege of CPU1
  [3:2] LIN1_EDMA1 — SYSCON LIN1_EDMA1[1:0] bit: LIN1 EDMA1 access privilege of CPU1
  [1:0] LIN1_CPUX — SYSCON LIN1_CPUX[1:0] bit: LIN1 CPUx access privilege of CPU1
0x734 C1_LIN2_AC ro — SYSCON CPU1 LIN2 access control read only register
  [5:4] LIN2_EDMA2 — SYSCON LIN2_EDMA2[1:0] bit: LIN2 EDMA2 access privilege of CPU1
  [3:2] LIN2_EDMA1 — SYSCON LIN2_EDMA1[1:0] bit: LIN2 EDMA1 access privilege of CPU1
  [1:0] LIN2_CPUX — SYSCON LIN2_CPUX[1:0] bit: LIN2 CPUx access privilege of CPU1
0x740 C1_CAN1_AC ro — SYSCON CPU1 CAN1 access control read only register
  [5:4] CAN1_EDMA2 — SYSCON CAN1_EDMA2[1:0] bit: CAN1 EDMA2 access privilege of CPU1
  [3:2] CAN1_EDMA1 — SYSCON CAN1_EDMA1[1:0] bit: CAN1 EDMA1 access privilege of CPU1
  [1:0] CAN1_CPUX — SYSCON CAN1_CPUX[1:0] bit: CAN1 CPUx access privilege of CPU1
0x744 C1_CANFD1_AC ro — SYSCON CPU1 CANFD1 access control read only register
  [5:4] CANFD1_EDMA2 — SYSCON CANFD1_EDMA2[1:0] bit: CANFD1 EDMA2 access privilege of CPU1
  [3:2] CANFD1_EDMA1 — SYSCON CANFD1_EDMA1[1:0] bit: CANFD1 EDMA1 access privilege of CPU1
  [1:0] CANFD1_CPUX — SYSCON CANFD1_CPUX[1:0] bit: CANFD1 CPUx access privilege of CPU1
0x748 C1_CANFD2_AC ro — SYSCON CPU1 CANFD2 access control read only register
  [5:4] CANFD2_EDMA2 — SYSCON CANFD2_EDMA2[1:0] bit: CANFD2 EDMA2 access privilege of CPU1
  [3:2] CANFD2_EDMA1 — SYSCON CANFD2_EDMA1[1:0] bit: CANFD2 EDMA1 access privilege of CPU1
  [1:0] CANFD2_CPUX — SYSCON CANFD2_CPUX[1:0] bit: CANFD2 CPUx access privilege of CPU1
0x750 C1_EPG_AC ro — SYSCON CPU1 EPG access control read only register
  [5:4] EPG_EDMA2 — SYSCON EPG_EDMA2[1:0] bit: EPG EDMA2 access privilege of CPU1
  [3:2] EPG_EDMA1 — SYSCON EPG_EDMA1[1:0] bit: EPG EDMA1 access privilege of CPU1
  [1:0] EPG_CPUX — SYSCON EPG_CPUX[1:0] bit: EPG CPUx access privilege of CPU1
0x754 C1_TRNG_AC ro — SYSCON CPU1 TRNG access control read only register
  [5:4] TRNG_EDMA2 — SYSCON TRNG_EDMA2[1:0] bit: TRNG EDMA2 access privilege of CPU1
  [3:2] TRNG_EDMA1 — SYSCON TRNG_EDMA1[1:0] bit: TRNG EDMA1 access privilege of CPU1
  [1:0] TRNG_CPUX — SYSCON TRNG_CPUX[1:0] bit: TRNG CPUx access privilege of CPU1
0x758 C1_XBAR_AC ro — SYSCON CPU1 XBAR access control read only register
  [5:4] XBAR_EDMA2 — SYSCON XBAR_EDMA2[1:0] bit: XBAR EDMA2 access privilege of CPU1
  [3:2] XBAR_EDMA1 — SYSCON XBAR_EDMA1[1:0] bit: XBAR EDMA1 access privilege of CPU1
  [1:0] XBAR_CPUX — SYSCON XBAR_CPUX[1:0] bit: XBAR CPUx access privilege of CPU1
0x760 C1_TIM1_AC ro — SYSCON CPU1 TIM1 access control read only register
  [5:4] TIM1_EDMA2 — SYSCON TIM1_EDMA2[1:0] bit: TIM1 EDMA2 access privilege of CPU1
  [3:2] TIM1_EDMA1 — SYSCON TIM1_EDMA1[1:0] bit: TIM1 EDMA1 access privilege of CPU1
  [1:0] TIM1_CPUX — SYSCON TIM1_CPUX[1:0] bit: TIM1 CPUx access privilege of CPU1
0x764 C1_TIM2_AC ro — SYSCON CPU1 TIM2 access control read only register
  [5:4] TIM2_EDMA2 — SYSCON TIM2_EDMA2[1:0] bit: TIM2 EDMA2 access privilege of CPU1
  [3:2] TIM2_EDMA1 — SYSCON TIM2_EDMA1[1:0] bit: TIM2 EDMA1 access privilege of CPU1
  [1:0] TIM2_CPUX — SYSCON TIM2_CPUX[1:0] bit: TIM2 CPUx access privilege of CPU1
0x76C C1_LPTIM_AC ro — SYSCON CPU1 LPTIM access control read only register
  [1:0] LPTIM_CPUX — SYSCON LPTIM_CPUX[1:0] bit: LPTIM CPUx access privilege of CPU1
{0x76C+4i} C1_UART{i}_AC ro (i=1..4) — SYSCON CPU1 UART{i} access control read only register
  [5:4] UART{i}_EDMA2 — SYSCON UART{i}_EDMA2[1:0] bit: UART{i} EDMA2 access privilege of CPU1
  [3:2] UART{i}_EDMA1 — SYSCON UART{i}_EDMA1[1:0] bit: UART{i} EDMA1 access privilege of CPU1
  [1:0] UART{i}_CPUX — SYSCON UART{i}_CPUX[1:0] bit: UART{i} CPUx access privilege of CPU1
0x780 C1_EDMA1_AC ro — SYSCON CPU1 EDMA1 access control read only register
  [1:0] DMA1_CPUX — SYSCON DMA1_CPUX[1:0] bit: DMA1 CPUx access privilege of CPU1
0x784 C1_EDMA2_AC ro — SYSCON CPU1 EDMA2 access control read only register
  [1:0] DMA2_CPUX — SYSCON DMA2_CPUX[1:0] bit: DMA2 CPUx access privilege of CPU1
0x788 C1_DMAMUX1_AC ro — SYSCON CPU1 DMAMUX1 access control read only register
  [1:0] DMAMUX1_CPUX — SYSCON DMAMUX1_CPUX[1:0] bit: DMAMUX1 CPUx access privilege of CPU1
0x78C C1_DMAMUX2_AC ro — SYSCON CPU1 DMAMUX2 access control read only register
  [1:0] DMAMUX2_CPUX — SYSCON DMAMUX2_CPUX[1:0] bit: DMAMUX2 CPUx access privilege of CPU1
0x790 C1_BTIM1_AC ro — SYSCON CPU1 BTIM1 access control read only register
  [5:4] BTIM1_EDMA2 — SYSCON BTIM1_EDMA2[1:0] bit: BTIM1 EDMA2 access privilege of CPU1
  [3:2] BTIM1_EDMA1 — SYSCON BTIM1_EDMA1[1:0] bit: BTIM1 EDMA1 access privilege of CPU1
  [1:0] BTIM1_CPUX — SYSCON BTIM1_CPUX[1:0] bit: BTIM1 CPUx access privilege of CPU1
0x794 C1_BTIM2_AC ro — SYSCON CPU1 BTIM2 access control read only register
  [5:4] BTIM2_EDMA2 — SYSCON BTIM2_EDMA2[1:0] bit: BTIM2 EDMA2 access privilege of CPU1
  [3:2] BTIM2_EDMA1 — SYSCON BTIM2_EDMA1[1:0] bit: BTIM2 EDMA1 access privilege of CPU1
  [1:0] BTIM2_CPUX — SYSCON BTIM2_CPUX[1:0] bit: BTIM2 CPUx access privilege of CPU1
0x7FC C1_PERIPH_AC_LOCK ro — SYSCON CPU1 access control lock read only register
  [0] LOCK_AC_WR — SYSCON LOCK_AC_WR bit: CPU1 peripheral access control register access privilege
0x800 C2_ADCA_AC ro — SYSCON CPU2 ADCA access control read only register
  [1:0] ADCA_CPUX — SYSCON ADCA_CPUX[1:0] bit: ADCA CPUx access privilege of CPU2
0x804 C2_ADCB_AC ro — SYSCON CPU2 ADCB access control read only register
  [1:0] ADCB_CPUX — SYSCON ADCB_CPUX[1:0] bit: ADCB CPUx access privilege of CPU2
0x808 C2_ADCC_AC ro — SYSCON CPU2 ADCC access control read only register
  [1:0] ADCC_CPUX — SYSCON ADCC_CPUX[1:0] bit: ADCC CPUx access privilege of CPU2
0x80C C2_ADCD_AC ro — SYSCON CPU2 ADCD access control read only register
  [1:0] ADCD_CPUX — SYSCON ADCD_CPUX[1:0] bit: ADCD CPUx access privilege of CPU2
{0x80C+4i} C2_CMPSS{i}_AC ro (i=1..11) — SYSCON CPU2 CMPSS{i} access control read only register
  [5:4] CMPSS{i}_EDMA2 — SYSCON CMPSS{i}_EDMA2[1:0] bit: CMPSS{i} EDMA2 access privilege of CPU2
  [3:2] CMPSS{i}_EDMA1 — SYSCON CMPSS{i}_EDMA1[1:0] bit: CMPSS{i} EDMA1 access privilege of CPU2
  [1:0] CMPSS{i}_CPUX — SYSCON CMPSS{i}_CPUX[1:0] bit: CMPSS{i} CPUx access privilege of CPU2
0x840 C2_DAC1_AC ro — SYSCON CPU2 DAC1 access control read only register
  [5:4] DAC1_EDMA2 — SYSCON DAC1_EDMA2[1:0] bit: DAC1 EDMA2 access privilege of CPU2
  [3:2] DAC1_EDMA1 — SYSCON DAC1_EDMA1[1:0] bit: DAC1 EDMA1 access privilege of CPU2
  [1:0] DAC1_CPUX — SYSCON DAC1_CPUX[1:0] bit: DAC1 CPUx access privilege of CPU2
0x844 C2_DAC3_AC ro — SYSCON CPU2 DAC3 access control read only register
  [5:4] DAC3_EDMA2 — SYSCON DAC3_EDMA2[1:0] bit: DAC3 EDMA2 access privilege of CPU2
  [3:2] DAC3_EDMA1 — SYSCON DAC3_EDMA1[1:0] bit: DAC3 EDMA1 access privilege of CPU2
  [1:0] DAC3_CPUX — SYSCON DAC3_CPUX[1:0] bit: DAC3 CPUx access privilege of CPU2
{0x84C+4i} C2_EPWM{i}_AC ro (i=1..18) — SYSCON CPU2 EPWM{i} access control read only register
  [5:4] EPWM{i}_EDMA2 — SYSCON EPWM{i}_EDMA2[1:0] bit: EPWM{i} EDMA2 access privilege of CPU2
  [3:2] EPWM{i}_EDMA1 — SYSCON EPWM{i}_EDMA1[1:0] bit: EPWM{i} EDMA1 access privilege of CPU2
  [1:0] EPWM{i}_CPUX — SYSCON EPWM{i}_CPUX[1:0] bit: EPWM{i} CPUx access privilege of CPU2
{0x89C+4i} C2_EQEP{i}_AC ro (i=1..6) — SYSCON CPU2 EQEP{i} access control read only register
  [5:4] EQEP{i}_EDMA2 — SYSCON EQEP{i}_EDMA2[1:0] bit: EQEP{i} EDMA2 access privilege of CPU2
  [3:2] EQEP{i}_EDMA1 — SYSCON EQEP{i}_EDMA1[1:0] bit: EQEP{i} EDMA1 access privilege of CPU2
  [1:0] EQEP{i}_CPUX — SYSCON EQEP{i}_CPUX[1:0] bit: EQEP{i} CPUx access privilege of CPU2
{0x8BC+4i} C2_ECAP{i}_AC ro (i=1..7) — SYSCON CPU2 ECAP{i} access control read only register
  [5:4] ECAP{i}_EDMA2 — SYSCON ECAP{i}_EDMA2[1:0] bit: ECAP{i} EDMA2 access privilege of CPU2
  [3:2] ECAP{i}_EDMA1 — SYSCON ECAP{i}_EDMA1[1:0] bit: ECAP{i} EDMA1 access privilege of CPU2
  [1:0] ECAP{i}_CPUX — SYSCON ECAP{i}_CPUX[1:0] bit: ECAP{i} CPUx access privilege of CPU2
{0x8DC+4i} C2_SDFM{i}_AC ro (i=1..4) — SYSCON CPU2 SDFM{i} access control read only register
  [5:4] SDFM{i}_EDMA2 — SYSCON SDFM{i}_EDMA2[1:0] bit: SDFM{i} EDMA2 access privilege of CPU2
  [3:2] SDFM{i}_EDMA1 — SYSCON SDFM{i}_EDMA1[1:0] bit: SDFM{i} EDMA1 access privilege of CPU2
  [1:0] SDFM{i}_CPUX — SYSCON SDFM{i}_CPUX[1:0] bit: SDFM{i} CPUx access privilege of CPU2
{0x8EC+4i} C2_CLB{i}_AC ro (i=1..6) — SYSCON CPU2 CLB{i} access control read only register
  [1:0] CLB{i}_CPUX — SYSCON CLB{i}_CPUX[1:0] bit: CLB{i} CPUx access privilege of CPU2
{0x90C+4i} C2_SPI{i}_AC ro (i=1..4) — SYSCON CPU2 SPI{i} access control read only register
  [5:4] SPI{i}_EDMA2 — SYSCON SPI{i}_EDMA2[1:0] bit: SPI{i} EDMA2 access privilege of CPU2
  [3:2] SPI{i}_EDMA1 — SYSCON SPI{i}_EDMA1[1:0] bit: SPI{i} EDMA1 access privilege of CPU2
  [1:0] SPI{i}_CPUX — SYSCON SPI{i}_CPUX[1:0] bit: SPI{i} CPUx access privilege of CPU2
0x920 C2_I2C1_AC ro — SYSCON CPU2 I2C1 access control read only register
  [5:4] I2C1_EDMA2 — SYSCON I2C1_EDMA2[1:0] bit: I2C1 EDMA2 access privilege of CPU2
  [3:2] I2C1_EDMA1 — SYSCON I2C1_EDMA1[1:0] bit: I2C1 EDMA1 access privilege of CPU2
  [1:0] I2C1_CPUX — SYSCON I2C1_CPUX[1:0] bit: I2C1 CPUx access privilege of CPU2
0x924 C2_I2C2_AC ro — SYSCON CPU2 I2C2 access control read only register
  [5:4] I2C2_EDMA2 — SYSCON I2C2_EDMA2[1:0] bit: I2C2 EDMA2 access privilege of CPU2
  [3:2] I2C2_EDMA1 — SYSCON I2C2_EDMA1[1:0] bit: I2C2 EDMA1 access privilege of CPU2
  [1:0] I2C2_CPUX — SYSCON I2C2_CPUX[1:0] bit: I2C2 CPUx access privilege of CPU2
0x928 C2_PMBUS_AC ro — SYSCON CPU2 PMBUS access control read only register
  [5:4] PMBUS_EDMA2 — SYSCON PMBUS_EDMA2[1:0] bit: PMBUS EDMA2 access privilege of CPU2
  [3:2] PMBUS_EDMA1 — SYSCON PMBUS_EDMA1[1:0] bit: PMBUS EDMA1 access privilege of CPU2
  [1:0] PMBUS_CPUX — SYSCON PMBUS_CPUX[1:0] bit: PMBUS CPUx access privilege of CPU2
0x930 C2_LIN1_AC ro — SYSCON CPU2 LIN1 access control read only register
  [5:4] LIN1_EDMA2 — SYSCON LIN1_EDMA2[1:0] bit: LIN1 EDMA2 access privilege of CPU2
  [3:2] LIN1_EDMA1 — SYSCON LIN1_EDMA1[1:0] bit: LIN1 EDMA1 access privilege of CPU2
  [1:0] LIN1_CPUX — SYSCON LIN1_CPUX[1:0] bit: LIN1 CPUx access privilege of CPU2
0x934 C2_LIN2_AC ro — SYSCON CPU2 LIN2 access control read only register
  [5:4] LIN2_EDMA2 — SYSCON LIN2_EDMA2[1:0] bit: LIN2 EDMA2 access privilege of CPU2
  [3:2] LIN2_EDMA1 — SYSCON LIN2_EDMA1[1:0] bit: LIN2 EDMA1 access privilege of CPU2
  [1:0] LIN2_CPUX — SYSCON LIN2_CPUX[1:0] bit: LIN2 CPUx access privilege of CPU2
0x940 C2_CAN1_AC ro — SYSCON CPU2 CAN1 access control read only register
  [5:4] CAN1_EDMA2 — SYSCON CAN1_EDMA2[1:0] bit: CAN1 EDMA2 access privilege of CPU2
  [3:2] CAN1_EDMA1 — SYSCON CAN1_EDMA1[1:0] bit: CAN1 EDMA1 access privilege of CPU2
  [1:0] CAN1_CPUX — SYSCON CAN1_CPUX[1:0] bit: CAN1 CPUx access privilege of CPU2
0x944 C2_CANFD1_AC ro — SYSCON CPU2 CANFD1 access control read only register
  [5:4] CANFD1_EDMA2 — SYSCON CANFD1_EDMA2[1:0] bit: CANFD1 EDMA2 access privilege of CPU2
  [3:2] CANFD1_EDMA1 — SYSCON CANFD1_EDMA1[1:0] bit: CANFD1 EDMA1 access privilege of CPU2
  [1:0] CANFD1_CPUX — SYSCON CANFD1_CPUX[1:0] bit: CANFD1 CPUx access privilege of CPU2
0x948 C2_CANFD2_AC ro — SYSCON CPU2 CANFD2 access control read only register
  [5:4] CANFD2_EDMA2 — SYSCON CANFD2_EDMA2[1:0] bit: CANFD2 EDMA2 access privilege of CPU2
  [3:2] CANFD2_EDMA1 — SYSCON CANFD2_EDMA1[1:0] bit: CANFD2 EDMA1 access privilege of CPU2
  [1:0] CANFD2_CPUX — SYSCON CANFD2_CPUX[1:0] bit: CANFD2 CPUx access privilege of CPU2
0x950 C2_EPG_AC ro — SYSCON CPU2 EPG access control read only register
  [5:4] EPG_EDMA2 — SYSCON EPG_EDMA2[1:0] bit: EPG EDMA2 access privilege of CPU2
  [3:2] EPG_EDMA1 — SYSCON EPG_EDMA1[1:0] bit: EPG EDMA1 access privilege of CPU2
  [1:0] EPG_CPUX — SYSCON EPG_CPUX[1:0] bit: EPG CPUx access privilege of CPU2
0x954 C2_TRNG_AC ro — SYSCON CPU2 TRNG access control read only register
  [5:4] TRNG_EDMA2 — SYSCON TRNG_EDMA2[1:0] bit: TRNG EDMA2 access privilege of CPU2
  [3:2] TRNG_EDMA1 — SYSCON TRNG_EDMA1[1:0] bit: TRNG EDMA1 access privilege of CPU2
  [1:0] TRNG_CPUX — SYSCON TRNG_CPUX[1:0] bit: TRNG CPUx access privilege of CPU2
0x958 C2_XBAR_AC ro — SYSCON CPU2 XBAR access control read only register
  [5:4] XBAR_EDMA2 — SYSCON XBAR_EDMA2[1:0] bit: XBAR EDMA2 access privilege of CPU2
  [3:2] XBAR_EDMA1 — SYSCON XBAR_EDMA1[1:0] bit: XBAR EDMA1 access privilege of CPU2
  [1:0] XBAR_CPUX — SYSCON XBAR_CPUX[1:0] bit: XBAR CPUx access privilege of CPU2
0x960 C2_TIM1_AC ro — SYSCON CPU2 TIM1 access control read only register
  [5:4] TIM1_EDMA2 — SYSCON TIM1_EDMA2[1:0] bit: TIM1 EDMA2 access privilege of CPU2
  [3:2] TIM1_EDMA1 — SYSCON TIM1_EDMA1[1:0] bit: TIM1 EDMA1 access privilege of CPU2
  [1:0] TIM1_CPUX — SYSCON TIM1_CPUX[1:0] bit: TIM1 CPUx access privilege of CPU2
0x964 C2_TIM2_AC ro — SYSCON CPU2 TIM2 access control read only register
  [5:4] TIM2_EDMA2 — SYSCON TIM2_EDMA2[1:0] bit: TIM2 EDMA2 access privilege of CPU2
  [3:2] TIM2_EDMA1 — SYSCON TIM2_EDMA1[1:0] bit: TIM2 EDMA1 access privilege of CPU2
  [1:0] TIM2_CPUX — SYSCON TIM2_CPUX[1:0] bit: TIM2 CPUx access privilege of CPU2
0x96C C2_LPTIM_AC ro — SYSCON CPU2 LPTIM access control read only register
  [1:0] LPTIM_CPUX — SYSCON LPTIM_CPUX[1:0] bit: LPTIM CPUx access privilege of CPU2
{0x96C+4i} C2_UART{i}_AC ro (i=1..4) — SYSCON CPU2 UART{i} access control read only register
  [5:4] UART{i}_EDMA2 — SYSCON UART{i}_EDMA2[1:0] bit: UART{i} EDMA2 access privilege of CPU2
  [3:2] UART{i}_EDMA1 — SYSCON UART{i}_EDMA1[1:0] bit: UART{i} EDMA1 access privilege of CPU2
  [1:0] UART{i}_CPUX — SYSCON UART{i}_CPUX[1:0] bit: UART{i} CPUx access privilege of CPU2
0x980 C2_EDMA1_AC ro — SYSCON CPU2 EDMA1 access control read only register
  [1:0] DMA1_CPUX — SYSCON DMA1_CPUX[1:0] bit: DMA1 CPUx access privilege of CPU2
0x984 C2_EDMA2_AC ro — SYSCON CPU2 EDMA2 access control read only register
  [1:0] DMA2_CPUX — SYSCON DMA2_CPUX[1:0] bit: DMA2 CPUx access privilege of CPU2
0x988 C2_DMAMUX1_AC ro — SYSCON CPU2 DMAMUX1 access control read only register
  [1:0] DMAMUX1_CPUX — SYSCON DMAMUX1_CPUX[1:0] bit: DMAMUX1 CPUx access privilege of CPU2
0x98C C2_DMAMUX2_AC ro — SYSCON CPU2 DMAMUX2 access control read only register
  [1:0] DMAMUX2_CPUX — SYSCON DMAMUX2_CPUX[1:0] bit: DMAMUX2 CPUx access privilege of CPU2
0x990 C2_BTIM1_AC ro — SYSCON CPU2 BTIM1 access control read only register
  [5:4] BTIM1_EDMA2 — SYSCON BTIM1_EDMA2[1:0] bit: BTIM1 EDMA2 access privilege of CPU2
  [3:2] BTIM1_EDMA1 — SYSCON BTIM1_EDMA1[1:0] bit: BTIM1 EDMA1 access privilege of CPU2
  [1:0] BTIM1_CPUX — SYSCON BTIM1_CPUX[1:0] bit: BTIM1 CPUx access privilege of CPU2
0x994 C2_BTIM2_AC ro — SYSCON CPU2 BTIM2 access control read only register
  [5:4] BTIM2_EDMA2 — SYSCON BTIM2_EDMA2[1:0] bit: BTIM2 EDMA2 access privilege of CPU2
  [3:2] BTIM2_EDMA1 — SYSCON BTIM2_EDMA1[1:0] bit: BTIM2 EDMA1 access privilege of CPU2
  [1:0] BTIM2_CPUX — SYSCON BTIM2_CPUX[1:0] bit: BTIM2 CPUx access privilege of CPU2
0x9FC C2_PERIPH_AC_LOCK ro — SYSCON CPU2 access control lock read only register
  [0] LOCK_AC_WR — SYSCON LOCK_AC_WR bit: CPU2 peripheral access control register access privilege
